# STM32WB55_CM0P register map
File version: 1.7
CPU: CM0 r0p1, little endian, MPU, no FPU, 4 interrupt priority bits
Registers are 32-bit, read-write, reset 0x0 unless marked. A register's access mark holds for its fields unless they carry their own. Offsets are from the block's base; [hi:lo] are bit positions; {n}, {i} and the like mark numbered series; 'fields as' and 'values as' point back to an identical list.

## DMA1 — Direct memory access controller
Base 0x40020000
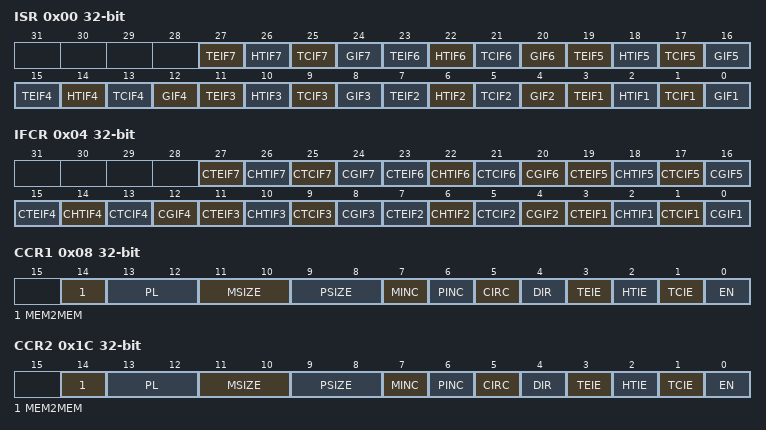
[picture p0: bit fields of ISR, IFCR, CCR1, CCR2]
0x00 ISR ro — interrupt status register
  [4n-1] TEIF{n} (n=1..7) — Channel x transfer error flag (x = 1 ..7)
  [4n-2] HTIF{n} (n=1..7) — Channel x half transfer flag (x = 1 ..7)
  [4n-3] TCIF{n} (n=1..7) — Channel x transfer complete flag (x = 1 ..7)
  [4n-4] GIF{n} (n=1..7) — Channel x global interrupt flag (x = 1 ..7)
0x04 IFCR wo — interrupt flag clear register
  [4n-1] CTEIF{n} (n=1..7) — Channel x transfer error clear (x = 1 ..7)
  [4n-2] CHTIF{n} (n=1..7) — Channel x half transfer clear (x = 1 ..7)
  [4n-3] CTCIF{n} (n=1..7) — Channel x transfer complete clear (x = 1 ..7)
  [4n-4] CGIF{n} (n=1..7) — Channel x global interrupt clear (x = 1 ..7)
0x08 CCR1 — channel x configuration register
  [14] MEM2MEM — Memory to memory mode
  [13:12] PL — Channel priority level
  [11:10] MSIZE — Memory size
  [9:8] PSIZE — Peripheral size
  [7] MINC — Memory increment mode
  [6] PINC — Peripheral increment mode
  [5] CIRC — Circular mode
  [4] DIR — Data transfer direction
  [3] TEIE — Transfer error interrupt enable
  [2] HTIE — Half transfer interrupt enable
  [1] TCIE — Transfer complete interrupt enable
  [0] EN — Channel enable
0x0C CNDTR1 — channel x number of data register
  [15:0] NDT — Number of data to transfer
0x10 CPAR1 — channel x peripheral address register
  [31:0] PA — Peripheral address
{0x0+0x14*i} CMAR{i} (i=1..7) — channel x memory address register
  [31:0] MA — Memory address
0x1C CCR2 — channel x configuration register
  fields as CCR1
0x20 CNDTR2 — channel x number of data register
  [15:0] NDT — Number of data to transfer
0x24 CPAR2 — channel x peripheral address register
  [31:0] PA — Peripheral address
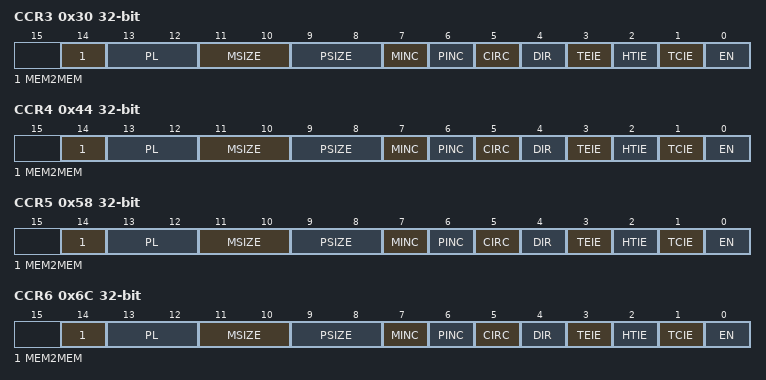
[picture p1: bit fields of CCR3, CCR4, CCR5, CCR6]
0x30 CCR3 — channel x configuration register
  fields as CCR1
0x34 CNDTR3 — channel x number of data register
  [15:0] NDT — Number of data to transfer
0x38 CPAR3 — channel x peripheral address register
  [31:0] PA — Peripheral address
0x44 CCR4 — channel x configuration register
  fields as CCR1
0x48 CNDTR4 — channel x number of data register
  [15:0] NDT — Number of data to transfer
0x4C CPAR4 — channel x peripheral address register
  [31:0] PA — Peripheral address
0x58 CCR5 — channel x configuration register
  fields as CCR1
0x5C CNDTR5 — channel x number of data register
  [15:0] NDT — Number of data to transfer
0x60 CPAR5 — channel x peripheral address register
  [31:0] PA — Peripheral address
0x6C CCR6 — channel x configuration register
  fields as CCR1
0x70 CNDTR6 — channel x number of data register
  [15:0] NDT — Number of data to transfer
0x74 CPAR6 — channel x peripheral address register
  [31:0] PA — Peripheral address
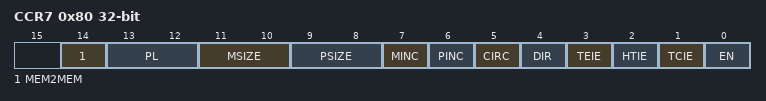
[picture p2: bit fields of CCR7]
0x80 CCR7 — channel x configuration register
  fields as CCR1
0x84 CNDTR7 — channel x number of data register
  [15:0] NDT — Number of data to transfer
0x88 CPAR7 — channel x peripheral address register
  [31:0] PA — Peripheral address

## DMA2 — Direct memory access controller
Base 0x40020400
Registers as DMA1; these are added or differ:
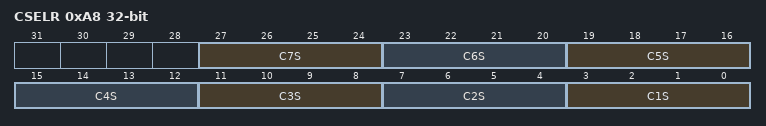
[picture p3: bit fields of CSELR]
0xA8 CSELR — channel selection register
  [4n-1:4n-4] C{n}S (n=1..7) — DMA channel {n} selection

## DMAMUX1 — Direct memory access Multiplexer
Base 0x40020800
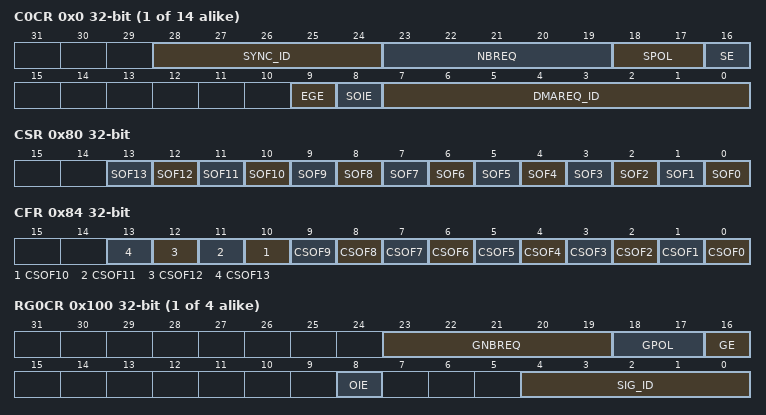
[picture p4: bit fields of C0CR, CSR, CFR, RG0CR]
{0x0+4i} C{i}CR (i=0..13) — DMA Multiplexer Channel {i} Control register
  [28:24] SYNC_ID
  [23:19] NBREQ — Nb request
  [18:17] SPOL — Sync polarity
  [16] SE — Synchronization enable
  [9] EGE — Event Generation Enable
  [8] SOIE — Synchronization Overrun Interrupt Enable
  [7:0] DMAREQ_ID — DMA Request ID
0x80 CSR ro — DMA Multiplexer Channel Status register
  [n] SOF{n} (n=0..13) — Synchronization Overrun Flag {n}
0x84 CFR wo — DMA Channel Clear Flag Register
  [n] CSOF{n} (n=0..13) — Synchronization Clear Overrun Flag {n}
{0x100+4i} RG{i}CR (i=0..3) — DMA Request Generator {i} Control Register
  [23:19] GNBREQ — Number of Request
  [18:17] GPOL — Generation Polarity
  [16] GE — Generation Enable
  [8] OIE — Overrun Interrupt Enable
  [4:0] SIG_ID — Signal ID
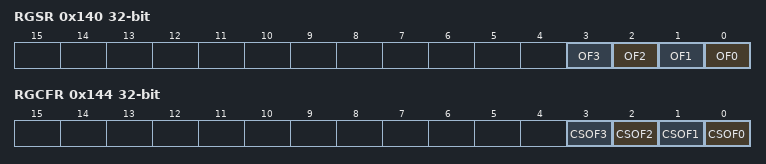
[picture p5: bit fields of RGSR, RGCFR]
0x140 RGSR ro — DMA Request Generator Status Register
  [n] OF{n} (n=0..3) — Generator Overrun Flag {n}
0x144 RGCFR ro — DMA Request Generator Clear Flag Register
  [n] CSOF{n} (n=0..3) — Generator Clear Overrun Flag {n}
